# MK20D7 register map
File version: 1.6
Registers are 32-bit, access per field, reset 0x0 unless marked. A register's access mark holds for its fields unless they carry their own. Offsets are from the block's base; [hi:lo] are bit positions; {n}, {i} and the like mark numbered series; 'fields as' and 'values as' point back to an identical list.

## DAC0 — 12-Bit Digital-to-Analog Converter
Base 0x400CC000; register names take the prefix DAC0_
{0x0+2i} DAT{i}L (i=0..15) 8-bit rw — DAC Data Low Register
  [7:0] DATA
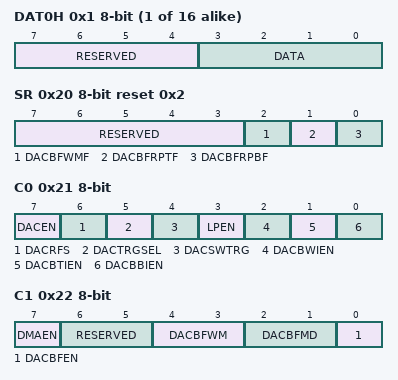
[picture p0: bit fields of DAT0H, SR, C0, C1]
{0x1+2i} DAT{i}H (i=0..15) 8-bit — DAC Data High Register
  [7:4] RESERVED ro, [3:0] DATA rw
0x20 SR 8-bit reset 0x2 — DAC Status Register
  [7:3] RESERVED ro
  [2] DACBFWMF rw — DAC buffer watermark flag
    0=The DAC buffer read pointer has not reached the watermark level; 1=The DAC buffer read pointer has reached the watermark level
  [1] DACBFRPTF rw — DAC buffer read pointer top position flag
    0=The DAC buffer read pointer is not zero; 1=The DAC buffer read pointer is zero
  [0] DACBFRPBF rw — DAC buffer read pointer bottom position flag
    0=The DAC buffer read pointer is not equal to the DACBFUP; 1=The DAC buffer read pointer is equal to the DACBFUP
0x21 C0 8-bit — DAC Control Register
  [7] DACEN rw — DAC enable
    0=The DAC system is disabled; 1=The DAC system is enabled
  [6] DACRFS rw — DAC Reference Select
    0=The DAC selets DACREF_1 as the reference voltage; 1=The DAC selets DACREF_2 as the reference voltage
  [5] DACTRGSEL rw — DAC trigger select
    0=The DAC hardware trigger is selected; 1=The DAC software trigger is selected
  [4] DACSWTRG wo — DAC software trigger
    0=The DAC soft trigger is not valid; 1=The DAC soft trigger is valid
  [3] LPEN rw — DAC low power control
    0=high power mode; 1=low power mode
  [2] DACBWIEN rw — DAC buffer watermark interrupt enable
    0=The DAC buffer watermark interrupt is disabled; 1=The DAC buffer watermark interrupt is enabled
  [1] DACBTIEN rw — DAC buffer read pointer top flag interrupt enable
    0=The DAC buffer read pointer top flag interrupt is disabled; 1=The DAC buffer read pointer top flag interrupt is enabled
  [0] DACBBIEN rw — DAC buffer read pointer bottom flag interrupt enable
    0=The DAC buffer read pointer bottom flag interrupt is disabled; 1=The DAC buffer read pointer bottom flag interrupt is enabled
0x22 C1 8-bit — DAC Control Register 1
  [7] DMAEN rw — DMA enable select
    0=DMA disabled; 1=DMA enabled. When DMA enabled, DMA request will be generated by original interrupts. And interrupts will not be presented on this module at the same time.
  [6:5] RESERVED ro
  [4:3] DACBFWM rw — DAC buffer watermark select
    0=1 word; 1=2 words; 2=3 words; 3=4 words
  [2:1] DACBFMD rw — DAC buffer work mode select
    0=Normal Mode; 1=Swing Mode; 2=One-Time Scan Mode
  [0] DACBFEN rw — DAC buffer enable
    0=Buffer read pointer disabled. The converted data is always the first word of the buffer.; 1=Buffer read pointer enabled. The converted data is the word that the read pointer points to. It means converted data can be from any word of the buffer.
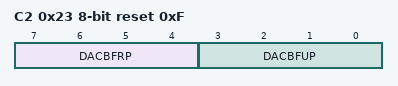
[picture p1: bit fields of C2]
0x23 C2 8-bit rw reset 0xF — DAC Control Register 2
  [7:4] DACBFRP — DAC buffer read pointer
  [3:0] DACBFUP — DAC buffer upper limit

## GPIOA — General Purpose Input/Output
Base 0x400FF000; register names take the prefix GPIOA_
0x00 PDOR rw — Port Data Output Register
  [31:0] PDO — Port Data Output
    0=Logic level 0 is driven on pin provided pin is configured for General Purpose Output; 1=Logic level 1 is driven on pin provided pin is configured for General Purpose Output
0x04 PSOR wo — Port Set Output Register
  [31:0] PTSO — Port Set Output
    0=Corresponding bit in PDORn does not change; 1=Corresponding bit in PDORn is set to logic one
0x08 PCOR wo — Port Clear Output Register
  [31:0] PTCO — Port Clear Output
    0=Corresponding bit in PDORn does not change; 1=Corresponding bit in PDORn is cleared to logic zero
0x0C PTOR wo — Port Toggle Output Register
  [31:0] PTTO — Port Toggle Output
    0=Corresponding bit in PDORn does not change; 1=Corresponding bit in PDORn is set to the inverse of its existing logic state
0x10 PDIR ro — Port Data Input Register
  [31:0] PDI — Port Data Input
    0=Pin logic level is logic zero or is configured for use by digital function; 1=Pin logic level is logic one
0x14 PDDR rw — Port Data Direction Register
  [31:0] PDD — Port data direction
    0=Pin is configured as general purpose input, if configured for the GPIO function; 1=Pin is configured for general purpose output, if configured for the GPIO function

## GPIOB — General Purpose Input/Output
Base 0x400FF040; register names take the prefix GPIOB_
Registers as GPIOA.

## GPIOC — General Purpose Input/Output
Base 0x400FF080; register names take the prefix GPIOC_
Registers as GPIOA.

## GPIOD — General Purpose Input/Output
Base 0x400FF0C0; register names take the prefix GPIOD_
Registers as GPIOA.

## GPIOE — General Purpose Input/Output
Base 0x400FF100; register names take the prefix GPIOE_
Registers as GPIOA.

## SysTick — System timer
Base 0xE000E010; register names take the prefix SYST_
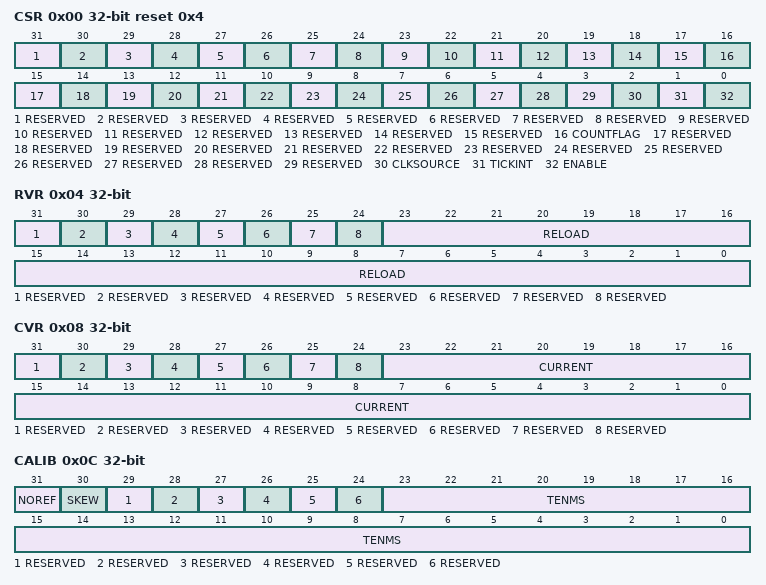
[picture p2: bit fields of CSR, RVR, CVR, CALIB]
0x00 CSR reset 0x4 — SysTick Control and Status Register
  [31] RESERVED ro
  [30] RESERVED ro
  [29] RESERVED ro
  [28] RESERVED ro
  [27] RESERVED ro
  [26] RESERVED ro
  [25] RESERVED ro
  [24] RESERVED ro
  [23] RESERVED ro
  [22] RESERVED ro
  [21] RESERVED ro
  [20] RESERVED ro
  [19] RESERVED ro
  [18] RESERVED ro
  [17] RESERVED ro
  [16] COUNTFLAG rw
  [15] RESERVED ro
  [14] RESERVED ro
  [13] RESERVED ro
  [12] RESERVED ro
  [11] RESERVED ro
  [10] RESERVED ro
  [9] RESERVED ro
  [8] RESERVED ro
  [7] RESERVED ro
  [6] RESERVED ro
  [5] RESERVED ro
  [4] RESERVED ro
  [3] RESERVED ro
  [2] CLKSOURCE rw
    0=external clock; 1=processor clock
  [1] TICKINT rw
    0=counting down to 0 does not assert the SysTick exception request; 1=counting down to 0 asserts the SysTick exception request
  [0] ENABLE rw
    0=counter disabled; 1=counter enabled
0x04 RVR — SysTick Reload Value Register
  [31] RESERVED ro
  [30] RESERVED ro
  [29] RESERVED ro
  [28] RESERVED ro
  [27] RESERVED ro
  [26] RESERVED ro
  [25] RESERVED ro
  [24] RESERVED ro
  [23:0] RELOAD rw — Value to load into the SysTick Current Value Register when the counter reaches 0
0x08 CVR — SysTick Current Value Register
  [31] RESERVED ro
  [30] RESERVED ro
  [29] RESERVED ro
  [28] RESERVED ro
  [27] RESERVED ro
  [26] RESERVED ro
  [25] RESERVED ro
  [24] RESERVED ro
  [23:0] CURRENT rw — Current value at the time the register is accessed
0x0C CALIB ro — SysTick Calibration Value Register
  [31] NOREF
    0=The reference clock is provided; 1=The reference clock is not provided
  [30] SKEW
    0=10ms calibration value is exact; 1=10ms calibration value is inexact, because of the clock frequency
  [29] RESERVED
  [28] RESERVED
  [27] RESERVED
  [26] RESERVED
  [25] RESERVED
  [24] RESERVED
  [23:0] TENMS — Reload value to use for 10ms timing

## MCM — Core Platform Miscellaneous Control Module
Base 0xE0080000; register names take the prefix MCM_
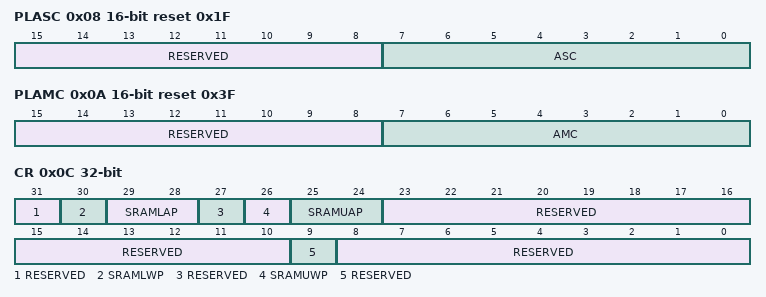
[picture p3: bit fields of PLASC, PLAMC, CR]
0x08 PLASC 16-bit ro reset 0x1F — Crossbar switch (AXBS) slave configuration
  [15:8] RESERVED
  [7:0] ASC — Each bit in the ASC field indicates if there is a corresponding connection to the crossbar switch's slave input port.
    0=A bus slave connection to AXBS input port n is absent; 1=A bus slave connection to AXBS input port n is present
0x0A PLAMC 16-bit ro reset 0x3F — Crossbar switch (AXBS) master configuration
  [15:8] RESERVED
  [7:0] AMC — Each bit in the AMC field indicates if there is a corresponding connection to the AXBS master input port.
    0=A bus master connection to AXBS input port n is absent; 1=A bus master connection to AXBS input port n is present
0x0C CR — Control register
  [31] RESERVED ro
  [30] SRAMLWP rw — SRAM_L write protect
  [29:28] SRAMLAP rw — SRAM_L arbitration priority
    0=Round robin; 1=Special round robin (favors SRAM backoor accesses over the processor); 2=Fixed priority. Processor has highest, backdoor has lowest; 3=Fixed priority. Backdoor has highest, processor has lowest
  [27] RESERVED ro
  [26] SRAMUWP rw — SRAM_U write protect
  [25:24] SRAMUAP rw — SRAM_U arbitration priority
    values as SRAMLAP
  [23:10] RESERVED ro
  [9] RESERVED ro
  [8:0] RESERVED ro
